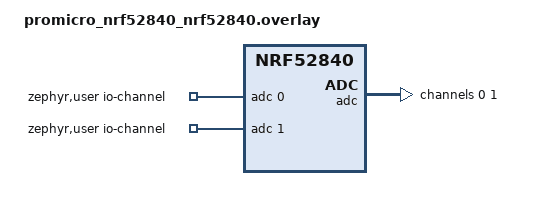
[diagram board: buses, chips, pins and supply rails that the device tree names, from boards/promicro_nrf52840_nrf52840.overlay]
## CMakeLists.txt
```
cmake_minimum_required(VERSION 3.20.0)
find_package(Zephyr REQUIRED HINTS $ENV{ZEPHYR_BASE})
project(duta_zephyr)

# The skrit contract + the shared portable core (header-only). src/ is on the
# path too so the portable common/duta_sniffer.h facade can include this
# platform's backend headers (duta_154_sniff.h / duta_ble_sniff.h).
target_include_directories(app PRIVATE
  ${CMAKE_CURRENT_SOURCE_DIR}/../../protocol
  ${CMAKE_CURRENT_SOURCE_DIR}/../common
  ${CMAKE_CURRENT_SOURCE_DIR}/src)
target_sources(app PRIVATE src/main.c)
target_sources_ifdef(CONFIG_DUTA_SNIFF app PRIVATE src/duta_ble_sniff.c)
target_sources_ifdef(CONFIG_DUTA_SNIFF_154 app PRIVATE src/duta_154_sniff.c)
# Unified build: both raw-radio backends + the runtime dispatch vtable.
target_sources_ifdef(CONFIG_DUTA_SNIFF_MULTI app PRIVATE
  src/duta_ble_sniff.c src/duta_154_sniff.c src/duta_sniffer_multi.c)
```

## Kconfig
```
# Duta zephyr app options.
config DUTA_SNIFF
	bool "Build the BLE advertising sniffer variant"
	depends on !BT && !DUTA_SNIFF_154 && !DUTA_SNIFF_MULTI
	help
	  Replace the UART DATA bridge with a raw-radio BLE advertising sniffer
	  (nRF only). The radio is driven directly — incompatible with the BLE
	  controller (BT) — to capture advertising PDUs on channels 37/38/39. DATA
	  becomes a stream of captured-packet records (kind = ble-sniff). Select via
	  `-DEXTRA_CONF_FILE=overlay-sniff.conf`.

config DUTA_SNIFF_154
	bool "Build the IEEE 802.15.4 (Zigbee/Thread) sniffer variant"
	depends on !BT && !DUTA_SNIFF_MULTI
	help
	  Replace the UART DATA bridge with a raw-radio IEEE 802.15.4 sniffer (nRF
	  only). The radio is driven directly in its 802.15.4 mode to capture frames
	  on channels 11-26 (Zigbee and Thread share this PHY/MAC). DATA becomes a
	  stream of captured-frame records (kind = ieee802154). One radio, so this is
	  mutually exclusive with the BLE sniffer. Select via
	  `-DEXTRA_CONF_FILE=overlay-sniff154.conf`.

config DUTA_SNIFF_MULTI
	bool "Build the unified runtime-switchable sniffer (BLE + 802.15.4)"
	depends on !BT
	help
	  Compile BOTH raw-radio sniffer backends into one image and switch the live
	  PHY at runtime via CFG_SET key 0x14 (DATA kind): 4 = BLE advertising
	  (channels 37/38/39), 7 = IEEE 802.15.4 (channels 11-26 — Zigbee, Thread,
	  and Matter-over-Thread, which share the PHY; the Wireshark dissector tells
	  them apart). DATA_DESC reflects the active link type so the extcap picks the
	  matching DLT. One nRF radio, so incompatible with the BLE controller (BT).
	  Boots in BLE mode. Select via `-DEXTRA_CONF_FILE=overlay-sniff-multi.conf`.

source "Kconfig.zephyr"
```

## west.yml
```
# Minimal west manifest so CI (and a fresh checkout) can resolve Zephyr.
# Inside an existing Zephyr workspace you don't need this — just `west build`.
manifest:
  remotes:
    - name: zephyrproject-rtos
      url-base: https://github.com/zephyrproject-rtos
  projects:
    - name: zephyr
      remote: zephyrproject-rtos
      revision: v4.2.0 # pinned so CI doesn't chase main; bump deliberately
      import:
        # Keep the CI clone lean — just what native_sim + nRF52840 need.
        name-allowlist:
          - cmsis
          - cmsis_6
          - hal_nordic
          - picolibc
  self:
    path: application
```

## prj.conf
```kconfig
# Common config — kept native_sim-safe (the CI build-check). USB/CDC and other
# board-specific bits live in boards/<board>.conf so they only apply on hardware.
CONFIG_PRINTK=y
CONFIG_GPIO=y
CONFIG_SERIAL=y
CONFIG_REBOOT=y
```

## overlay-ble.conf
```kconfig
# BLE transport overlay — carries the skrit-mux stream over a Nordic UART Service
# (NUS) GATT pipe instead of USB CDC. Build with:
#
#   west build -b nrf52840dk/nrf52840 platforms/zephyr -- -DEXTRA_CONF_FILE=overlay-ble.conf
#
# CONFIG_BT makes src/main.c select the BLE transport (see the #if CONFIG_BT block).
CONFIG_BT=y
CONFIG_BT_PERIPHERAL=y
CONFIG_BT_DEVICE_NAME="Duta nRF52840"
CONFIG_BT_DEVICE_APPEARANCE=0

# GATT server with our hand-rolled NUS service (BT_GATT_SERVICE_DEFINE).
CONFIG_BT_GATT_DYNAMIC_DB=y
CONFIG_BT_ATT_PREPARE_COUNT=2

# Larger ATT MTU so console bursts need fewer notifications.
CONFIG_BT_L2CAP_TX_MTU=247
CONFIG_BT_BUF_ACL_TX_SIZE=251
CONFIG_BT_BUF_ACL_RX_SIZE=251

# Security: LE Secure Connections pairing (ECDH P-256) so the air link is
# encrypted and NOT passively sniffable. A Duta has no display/keyboard, so the
# IO capability is NoInputNoOutput → "Just Works" pairing (encrypted, passively
# secure under LESC). The DATA/CMD characteristics require encryption, so a central
# must pair before it can write or subscribe.
CONFIG_BT_SMP=y
CONFIG_BT_BONDABLE=y

# Persist bonds across reboots: the settings subsystem over NVS on the flash map,
# so a paired host reconnects without re-pairing.
CONFIG_BT_SETTINGS=y
CONFIG_SETTINGS=y
CONFIG_FLASH=y
CONFIG_FLASH_MAP=y
CONFIG_NVS=y

# Per-device identity: set the advertised name to Duta-XXXX (from the BLE address)
# at runtime, so multiple Dutas are distinguishable in a scan.
CONFIG_BT_DEVICE_NAME_DYNAMIC=y
CONFIG_BT_DEVICE_NAME_MAX=24

# Keep the DATA-UART bridge + outputs + reboot from the base config.
CONFIG_SERIAL=y
CONFIG_GPIO=y
CONFIG_REBOOT=y
```

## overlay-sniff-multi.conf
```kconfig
# Unified runtime-switchable sniffer (BLE + IEEE 802.15.4), USB transport.
#   west build -b promicro_nrf52840/nrf52840 platforms/zephyr -- -DEXTRA_CONF_FILE=overlay-sniff-multi.conf
# Both raw-radio backends are compiled in and dispatched through a vtable; the
# host switches the live PHY at runtime with CFG_SET key 0x14 (DATA kind):
#   4 = BLE advertising · 7 = IEEE 802.15.4 (Zigbee / Thread / Matter-over-Thread)
# The radio is driven directly, so the BLE controller must stay off (BT=n, the
# default for the USB build). Boots in BLE mode.
CONFIG_DUTA_SNIFF_MULTI=y
# Carries the 802.15.4 backend (records up to ~137 B) — give the main stack the
# same headroom the single-154 build uses.
CONFIG_MAIN_STACK_SIZE=4096
```

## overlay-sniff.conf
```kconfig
# BLE advertising sniffer variant (USB transport).
#   west build -b promicro_nrf52840/nrf52840 platforms/zephyr -- -DEXTRA_CONF_FILE=overlay-sniff.conf
# The radio is driven directly, so the BLE controller must stay off (BT=n,
# the default for the USB build) and nothing else may claim the radio.
CONFIG_DUTA_SNIFF=y
```

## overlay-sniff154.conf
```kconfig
# IEEE 802.15.4 (Zigbee/Thread) sniffer variant (USB transport).
#   west build -b promicro_nrf52840/nrf52840 platforms/zephyr -- -DEXTRA_CONF_FILE=overlay-sniff154.conf
# The radio is driven directly in 802.15.4 mode, so the BLE controller must stay
# off (BT=n, the default for the USB build) and nothing else may claim the radio.
CONFIG_DUTA_SNIFF_154=y
# 802.15.4 records are large (up to ~137 B) and the enlarged send buffers push
# the main stack — give it headroom (the default is too tight for this path).
CONFIG_MAIN_STACK_SIZE=4096
```

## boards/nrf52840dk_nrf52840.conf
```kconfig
# nRF52840 DK — bring up the USB device stack + a CDC ACM port for the mux link,
# and the interrupt-driven UART API that cdc-acm needs.
CONFIG_USB_DEVICE_STACK=y
CONFIG_USB_DEVICE_PRODUCT="Duta nRF52840"
CONFIG_USB_DEVICE_VID=0x1209
CONFIG_USB_DEVICE_PID=0x5d10
CONFIG_USB_CDC_ACM=y
CONFIG_UART_INTERRUPT_DRIVEN=y
CONFIG_UART_LINE_CTRL=y
CONFIG_REBOOT=y
CONFIG_GPIO=y
```

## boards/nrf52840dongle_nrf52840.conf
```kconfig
# nRF52840 Dongle — same USB CDC ACM mux link as the DK. The dongle ships with a
# UF2/Open bootloader, so REBOOT(bootloader) drops straight back into DFU.
CONFIG_USB_DEVICE_STACK=y
CONFIG_USB_DEVICE_PRODUCT="Duta nRF52840 dongle"
CONFIG_USB_DEVICE_VID=0x1209
CONFIG_USB_DEVICE_PID=0x5d10
CONFIG_USB_CDC_ACM=y
CONFIG_UART_INTERRUPT_DRIVEN=y
CONFIG_UART_LINE_CTRL=y
CONFIG_REBOOT=y
CONFIG_GPIO=y
```

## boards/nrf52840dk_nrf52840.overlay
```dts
// nRF52840 DK — Duta transport map.
//   * CMD + DATA mux  -> a CDC ACM port on the USB device controller.
//   * DATA console     -> UART1 on header pins P1.01 (TX) / P1.02 (RX).
//   * Status LED       -> led0 (onboard) is the only default output; other
//                         fixtures are added at runtime via provisioning.
#include <zephyr/dt-bindings/pinctrl/nrf-pinctrl.h>

/ {
	aliases {
		duta-data = &uart1;
	};
};

&zephyr_udc0 {
	cdc_acm_uart0: cdc_acm_uart0 {
		compatible = "zephyr,cdc-acm-uart";
	};
};

&pinctrl {
	uart1_default: uart1_default {
		group1 {
			psels = <NRF_PSEL(UART_TX, 1, 1)>,
			        <NRF_PSEL(UART_RX, 1, 2)>;
		};
	};

	uart1_sleep: uart1_sleep {
		group1 {
			psels = <NRF_PSEL(UART_TX, 1, 1)>,
			        <NRF_PSEL(UART_RX, 1, 2)>;
			low-power-enable;
		};
	};
};

&uart1 {
	status = "okay";
	current-speed = <115200>;
	pinctrl-0 = <&uart1_default>;
	pinctrl-1 = <&uart1_sleep>;
	pinctrl-names = "default", "sleep";
};
```

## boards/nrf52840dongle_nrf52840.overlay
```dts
// nRF52840 Dongle — Duta transport map. The dongle has no debug UART, so DATA
// uses UART1 on two exposed castellated pads (P1.10 TX / P1.13 RX — adjust to
// your wiring). CMD + DATA still mux over a CDC ACM port. Outputs reuse the
// on-board LEDs (green led0 + two of the RGB channels).
#include <zephyr/dt-bindings/pinctrl/nrf-pinctrl.h>

/ {
	aliases {
		duta-data = &uart1;
	};
};

&zephyr_udc0 {
	cdc_acm_uart0: cdc_acm_uart0 {
		compatible = "zephyr,cdc-acm-uart";
	};
};

&pinctrl {
	uart1_default: uart1_default {
		group1 {
			psels = <NRF_PSEL(UART_TX, 1, 10)>,
			        <NRF_PSEL(UART_RX, 1, 13)>;
		};
	};

	uart1_sleep: uart1_sleep {
		group1 {
			psels = <NRF_PSEL(UART_TX, 1, 10)>,
			        <NRF_PSEL(UART_RX, 1, 13)>;
			low-power-enable;
		};
	};
};

&uart1 {
	status = "okay";
	current-speed = <115200>;
	pinctrl-0 = <&uart1_default>;
	pinctrl-1 = <&uart1_sleep>;
	pinctrl-names = "default", "sleep";
};
```

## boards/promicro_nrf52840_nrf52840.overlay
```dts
// Pro Micro nRF52840 — the "nice!nano v2 compatible" / SuperMini clone family.
// Board facts come from the upstream Zephyr board (boards/others/promicro_nrf52840):
//   * led0 = P0.15 (onboard blue LED), uart0 routed to the silkscreened TX/RX
//     pads (P0.09 TX / P0.10 RX; the NFC pins, freed as GPIO by the board UICR),
//     and a USB CDC ACM (cdc_acm_uart0) already in the board DTS.
// This overlay only adds OUR Duta wiring:
//   * CMD + DATA mux   -> the board's USB CDC ACM (BLE alt via overlay-ble.conf).
//   * DATA console      -> uart0, remapped to TX P0.06 / RX P0.08 (see &pinctrl).
//   * Status LED        -> led0 (the onboard blue LED) — the only default output.
//   External fixtures (relays, etc.) are NOT a compiled default: add them at
//   runtime via provisioning on the free broken-out pads.

#include <zephyr/dt-bindings/adc/adc.h>
#include <zephyr/dt-bindings/adc/nrf-saadc.h>
#include <zephyr/dt-bindings/pinctrl/nrf-pinctrl.h>

/ {
	aliases {
		duta-data = &uart0; // led0 (status LED) is already aliased by the board
	};

	// Two ADC inputs (skrit inputs 0 and 1), both internal — no broken-out pin:
	//   ch 0 = NRF_SAADC_VDD     → "Supply (mV)": the regulated rail (~3.0–3.3 V).
	//   ch 1 = NRF_SAADC_VDDHDIV5 → "Battery (mV)": VDDH/5; main.c ×5. On this
	//     nice!nano-clone family VDDH is fed from the LiPo (HV mode), so this reads
	//     the cell — but it tracks VDDH, so it reads HIGH on USB (~charge voltage),
	//     not the battery. The board's labelled P0.04 battery divider is mis-wired
	//     to P0.24 (no SAADC channel) upstream, so VDDHDIV5 is the usable path.
	// For an external analog pad instead, point a channel at <NRF_SAADC_AINx>
	// (AIN0 = P0.02, AIN2 = P0.04) and drop the ×5 in main.c for that index.
	zephyr,user {
		io-channels = <&adc 0>, <&adc 1>;
	};
};

&adc {
	status = "okay";
	#address-cells = <1>;
	#size-cells = <0>;

	channel@0 {
		reg = <0>;
		zephyr,gain = "ADC_GAIN_1_6";
		zephyr,reference = "ADC_REF_INTERNAL";
		zephyr,acquisition-time = <ADC_ACQ_TIME_DEFAULT>;
		zephyr,input-positive = <NRF_SAADC_VDD>;
		zephyr,resolution = <12>;
	};
	channel@1 {
		reg = <1>;
		zephyr,gain = "ADC_GAIN_1_6";
		zephyr,reference = "ADC_REF_INTERNAL";
		zephyr,acquisition-time = <ADC_ACQ_TIME_DEFAULT>;
		zephyr,input-positive = <NRF_SAADC_VDDHDIV5>; // battery via VDDH/5 (×5 in fw)
		zephyr,resolution = <12>;
	};
};

// Remap the DATA console (uart0) OFF the board-default silkscreen pads
// (P0.09 TX / P0.10 RX) to P0.06 TX / P0.08 RX. P0.10 is the nRF NFC1 pad — even
// with a pull-up it floats noisy as a UART RX and dumps garbage onto the Console
// (UART-bridge) source. P0.06/P0.08 are plain GPIO; bias RX high so an unwired
// bridge idles clean (a driven target overrides the weak pull). TX is an output
// and needs no bias. The sleep state is remapped to match.
&pinctrl {
	uart0_default {
		group1 {
			psels = <NRF_PSEL(UART_TX, 0, 6)>;
		};
		group2 {
			psels = <NRF_PSEL(UART_RX, 0, 8)>;
			bias-pull-up;
		};
	};
	uart0_sleep {
		group1 {
			psels = <NRF_PSEL(UART_TX, 0, 6)>,
				<NRF_PSEL(UART_RX, 0, 8)>;
			low-power-enable;
		};
	};
};
```

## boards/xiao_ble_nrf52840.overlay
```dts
// Seeed XIAO nRF52840 (Zephyr board xiao_ble). Board facts come from the upstream
// Zephyr board: uart0 is routed to the silkscreened TX/RX pads (D6 P1.11 / D7
// P1.12), there's a USB device controller (zephyr_udc0), and an onboard RGB user
// LED (led0 red P0.26, led1 green P0.30, led2 blue P0.06; active low), all of
// which the board already aliases. This overlay only adds OUR Duta wiring:
//   * CMD + DATA mux  -> a CDC ACM port on the USB device controller.
//   * DATA console     -> uart0 (the D6/D7 pads).
//   * Status LED       -> led0 (the RGB's red channel) — the only default output.
//     Relays / external fixtures are provisioned at runtime onto free pads via
//     Configure Device, not a fact about this board.

#include <zephyr/dt-bindings/adc/adc.h>
#include <zephyr/dt-bindings/adc/nrf-saadc.h>

/ {
	aliases {
		duta-data = &uart0; // led0/led1/led2 are already aliased by the board
	};

	// Two internal ADC inputs (skrit inputs 0/1): ch0 = VDD ("Supply (mV)", the
	// regulated rail); ch1 = VDDHDIV5 ("Battery (mV)", VDDH/5 ×5 in fw — the cell
	// on this nice!nano-class board, but reads high on USB). No pin needed.
	zephyr,user {
		io-channels = <&adc 0>, <&adc 1>;
	};
};

// The CDC ACM that carries the mux link (main.c looks for cdc_acm_uart0).
&zephyr_udc0 {
	cdc_acm_uart0: cdc_acm_uart0 {
		compatible = "zephyr,cdc-acm-uart";
	};
};

&uart0 {
	status = "okay";
	current-speed = <115200>;
};

&adc {
	status = "okay";
	#address-cells = <1>;
	#size-cells = <0>;

	channel@0 {
		reg = <0>;
		zephyr,gain = "ADC_GAIN_1_6";
		zephyr,reference = "ADC_REF_INTERNAL";
		zephyr,acquisition-time = <ADC_ACQ_TIME_DEFAULT>;
		zephyr,input-positive = <NRF_SAADC_VDD>;
		zephyr,resolution = <12>;
	};
	channel@1 {
		reg = <1>;
		zephyr,gain = "ADC_GAIN_1_6";
		zephyr,reference = "ADC_REF_INTERNAL";
		zephyr,acquisition-time = <ADC_ACQ_TIME_DEFAULT>;
		zephyr,input-positive = <NRF_SAADC_VDDHDIV5>; // battery via VDDH/5 (×5 in fw)
		zephyr,resolution = <12>;
	};
};
```

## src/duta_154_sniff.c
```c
// duta_154_sniff.c — raw-radio IEEE 802.15.4 sniffer (nRF52840).
// ============================================================================
// The ieee802154 DATA backend. With CONFIG_DUTA_SNIFF_154, the nRF radio is
// driven directly in its 802.15.4 mode (O-QPSK, 250 kbps) — the same silicon
// the BLE sniffer uses, different MODE. It listens promiscuously and captures
// MAC frames; each is emitted on the DATA channel as one record (PROTOCOL.md
// "IEEE 802.15.4 sniffer"):
//   ts_ms(4 LE) · channel(1, 11..26) · rssi(1, signed dBm) · lqi(1) ·
//     flags(1, bit0=FCS ok) · psdu_len(1) · psdu…
// The radio handles the O-QPSK PHY, the SFD, and the 16-bit FCS in hardware, so
// (unlike the BLE path) there's no software de-whitening; bad-FCS frames drop.
//
// Channel strategy: 802.15.4 networks live on ONE channel (not repeated across
// channels like BLE advertising), and we don't know which. So we dwell on a
// channel and hop to the next (11→26) only after it stays quiet for DWELL_MS,
// resetting the timer whenever a frame lands — i.e. we drift until we find the
// active channel, then stick there. (A fixed channel via CFG is a future knob.)
//
// NOTE: the radio register setup below follows the nRF52840 PS 802.15.4 mode;
// the values marked CONFIRM should be validated against live capture.
// ============================================================================
#include <nrfx.h> // MDK: NRF_RADIO + the RADIO_* register bitfields
#include <string.h>
#include <zephyr/kernel.h>

#include "duta_154_sniff.h"

// Implemented by the platform main: wakes the frame-consumer thread (event-driven
// instead of polling take()). Weak no-op default — matches the ESP backend's
// contract (duta_154_sniff_esp.c). This raw-register backend detects RX by polling
// EVENTS_END in take(), so it has no RX-complete callback to fire the hook from;
// it stays a default no-op here and the consumer thread's sem timeout drives the
// drain + channel hop. Wiring the RADIO END IRQ to call this is the future step
// (see NRF_ASYNC_REPORT.md) — left untouched because it can't be verified without
// hardware and a mis-armed radio IRQ would silently break capture.
__attribute__((weak)) void duta_sniffer_notify(void) {}

#define CH_MIN 11
#define CH_MAX 26
#define N_CHAN (CH_MAX - CH_MIN + 1)
#define DWELL_MS 400 // hop away from a quiet channel after this long

static uint8_t rx_buf[1 + 127 + 4]; // PHR(1) + max PSDU(127) + slack
static uint8_t tx_buf[1 + 127];     // PHR(1) + MAC frame (radio appends the FCS)
static uint8_t chan;                // current channel (11..26)
static uint8_t fixed_chan;          // 0 = auto-hop; 11..26 = pinned channel
static uint32_t last_hop_ms;
static bool sniff_active;

// 802.15.4 channel k (11..26) is 2405 + 5*(k-11) MHz; FREQUENCY = MHz - 2400.
static uint8_t chan_freq(uint8_t ch) { return (uint8_t)(5 * (ch - 10)); }

static void radio_arm(uint8_t ch) {
  NRF_RADIO->FREQUENCY = chan_freq(ch);
  NRF_RADIO->EVENTS_END = 0;
  NRF_RADIO->EVENTS_DISABLED = 0;
  NRF_RADIO->TASKS_RXEN = 1; // READY_START short kicks RX automatically
}

static void radio_rearm(uint8_t ch) {
  uint32_t guard = 100000;
  while (NRF_RADIO->STATE != RADIO_STATE_STATE_Disabled && guard--) { /* settle */ }
  radio_arm(ch);
}

void duta_154_sniff_init(void) {
  NRF_RADIO->POWER = 0;
  NRF_RADIO->POWER = 1;
  NRF_RADIO->MODE = (RADIO_MODE_MODE_Ieee802154_250Kbit << RADIO_MODE_MODE_Pos);
  // 802.15.4 on-air frame: PHR is one byte (7-bit length), no S0/S1. The length
  // field counts the PSDU *including* the 2-byte FCS (CRCINC = Include). The
  // radio frames on the SFD (0xA7) with a 32-bit zero preamble — no access addr.
  NRF_RADIO->PCNF0 = (8 << RADIO_PCNF0_LFLEN_Pos) |
                     (RADIO_PCNF0_PLEN_32bitZero << RADIO_PCNF0_PLEN_Pos) |
                     (RADIO_PCNF0_CRCINC_Include << RADIO_PCNF0_CRCINC_Pos);
  NRF_RADIO->PCNF1 = (127 << RADIO_PCNF1_MAXLEN_Pos); // no whitening, no base addr
  NRF_RADIO->SFD = 0xA7; // the 802.15.4 start-of-frame delimiter
  // 802.15.4 FCS: 16-bit, poly x^16+x^12+x^5+1 = 0x011021, init 0. SKIPADDR set
  // to the dedicated 802.15.4 value so the radio computes the FCS over the PSDU.
  NRF_RADIO->CRCCNF = (RADIO_CRCCNF_LEN_Two << RADIO_CRCCNF_LEN_Pos) |
                      (RADIO_CRCCNF_SKIPADDR_Ieee802154 << RADIO_CRCCNF_SKIPADDR_Pos);
  NRF_RADIO->CRCPOLY = 0x011021u;
  NRF_RADIO->CRCINIT = 0u;
  NRF_RADIO->PACKETPTR = (uint32_t)rx_buf;
  NRF_RADIO->SHORTS = RADIO_SHORTS_READY_START_Msk | RADIO_SHORTS_END_DISABLE_Msk |
                      RADIO_SHORTS_ADDRESS_RSSISTART_Msk;
}

void duta_154_sniff_start(void) {
  if (sniff_active) return;
  sniff_active = true;
  chan = fixed_chan ? fixed_chan : CH_MIN;
  last_hop_ms = k_uptime_get_32();
  radio_arm(chan);
}

void duta_154_sniff_set_channel(uint8_t ch) {
  fixed_chan = (ch >= CH_MIN && ch <= CH_MAX) ? ch : 0; // out of range => auto-hop
  chan = fixed_chan ? fixed_chan : CH_MIN;
  last_hop_ms = k_uptime_get_32();
  if (sniff_active) {
    NRF_RADIO->TASKS_DISABLE = 1;
    radio_rearm(chan); // retune now
  }
}

uint8_t duta_154_sniff_get_channel(void) { return chan; }

void duta_154_sniff_tx(const uint8_t *mac, uint16_t maclen) {
  if (maclen == 0 || maclen > 125) return; // +2 FCS must fit a 127-byte PSDU
  // Stop RX, transmit, then return to RX on the same channel. Single-threaded
  // with take(), so no concurrency with the receive path.
  NRF_RADIO->TASKS_DISABLE = 1;
  uint32_t guard = 100000;
  while (NRF_RADIO->STATE != RADIO_STATE_STATE_Disabled && guard--) { /* settle */ }

  tx_buf[0] = (uint8_t)(maclen + 2); // PHR length includes the 2-byte FCS (CRCINC)
  memcpy(tx_buf + 1, mac, maclen);   // the radio computes + appends the FCS
  NRF_RADIO->PACKETPTR = (uint32_t)tx_buf;
  NRF_RADIO->FREQUENCY = chan_freq(chan);
  NRF_RADIO->EVENTS_END = 0;
  NRF_RADIO->EVENTS_DISABLED = 0;
  NRF_RADIO->TASKS_TXEN = 1; // READY_START kicks TX; END_DISABLE disables after
  guard = 2000000;
  while (!NRF_RADIO->EVENTS_END && guard--) { /* wait for TX to finish */ }
  NRF_RADIO->EVENTS_END = 0;

  // Re-arm RX (restore the receive buffer first) if we're still sniffing.
  guard = 100000;
  while (NRF_RADIO->STATE != RADIO_STATE_STATE_Disabled && guard--) { /* settle */ }
  NRF_RADIO->PACKETPTR = (uint32_t)rx_buf;
  if (sniff_active) radio_arm(chan);
}

void duta_154_sniff_stop(void) {
  if (!sniff_active) return;
  sniff_active = false;
  NRF_RADIO->TASKS_DISABLE = 1;
  uint32_t guard = 100000;
  while (NRF_RADIO->STATE != RADIO_STATE_STATE_Disabled && guard--) { /* settle */ }
  NRF_RADIO->EVENTS_END = 0;
}

bool duta_154_sniff_is_on(void) { return sniff_active; }

uint16_t duta_154_sniff_take(uint8_t *out, uint16_t cap) {
  if (!sniff_active) return 0;

  if (!NRF_RADIO->EVENTS_END) {
    // No frame yet — hop away from a channel that has stayed quiet too long
    // (unless pinned to a fixed channel, in which case we just keep listening).
    if (!fixed_chan && (k_uptime_get_32() - last_hop_ms) >= DWELL_MS) {
      NRF_RADIO->TASKS_DISABLE = 1;
      chan = (uint8_t)(chan + 1);
      if (chan > CH_MAX) chan = CH_MIN;
      last_hop_ms = k_uptime_get_32();
      radio_rearm(chan);
    }
    return 0;
  }
  NRF_RADIO->EVENTS_END = 0;

  uint8_t crc_ok = (uint8_t)(NRF_RADIO->CRCSTATUS & 1u);
  int8_t rssi = (int8_t)(-(int32_t)(NRF_RADIO->RSSISAMPLE)); // magnitude -> signed dBm
  uint8_t cur = chan;
  uint8_t len = (uint8_t)(rx_buf[0] & 0x7Fu); // PHR length (PSDU incl. 2-byte FCS)

  // Traffic here — stay on this channel and re-arm. END_DISABLE already fired.
  last_hop_ms = k_uptime_get_32();
  radio_rearm(cur);

  if (!crc_ok || len < 2 || len > 127) return 0; // drop bad-FCS / impossible
  uint16_t need = 4 + 1 + 1 + 1 + 1 + 1 + len;
  if (need > cap) return 0;

  uint32_t ts = k_uptime_get_32();
  uint16_t n = 0;
  out[n++] = (uint8_t)ts;
  out[n++] = (uint8_t)(ts >> 8);
  out[n++] = (uint8_t)(ts >> 16);
  out[n++] = (uint8_t)(ts >> 24);
  out[n++] = cur;            // channel 11..26
  out[n++] = (uint8_t)rssi;  // signed dBm
  out[n++] = 0xFF;           // LQI not measured yet — placeholder (CONFIRM)
  out[n++] = 0x01;           // flags: bit0 = FCS ok (we dropped bad-FCS above)
  out[n++] = len;            // PSDU length (includes FCS)
  memcpy(out + n, rx_buf + 1, len);
  return (uint16_t)(n + len);
}
```

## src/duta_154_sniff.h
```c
// duta_154_sniff.h — raw-radio IEEE 802.15.4 sniffer (nRF; CONFIG_DUTA_SNIFF_154).
// Same shape as duta_ble_sniff.h, different radio mode — the nRF52840's radio
// also does 802.15.4 (the PHY/MAC under Zigbee AND Thread).
#ifndef DUTA_154_SNIFF_H
#define DUTA_154_SNIFF_H

#include <stdbool.h>
#include <stdint.h>

// Configure the radio for 802.15.4 sniffing (call once).
void duta_154_sniff_init(void);

// Start / stop capturing — backs the "Sniffing" virtual output. Idempotent.
void duta_154_sniff_start(void);
void duta_154_sniff_stop(void);
bool duta_154_sniff_is_on(void);

// If a frame was captured since the last call (and sniffing is on), write one
// DATA record into `out` (cap bytes) and return its length; else return 0. The
// sniffer dwells on a channel and hops (11..26) when it goes quiet, sticking
// wherever traffic appears. Record layout: see duta_154_sniff.c / PROTOCOL.md.
uint16_t duta_154_sniff_take(uint8_t *out, uint16_t cap);

// Pin the sniffer to one channel (11..26), or 0 to resume auto-hopping. Surfaced
// over SERIAL_SET (the baud field carries the channel). Takes effect immediately.
void duta_154_sniff_set_channel(uint8_t ch);
// The channel currently being listened on (the pinned one, or the live hop).
uint8_t duta_154_sniff_get_channel(void);

// Transmit one 802.15.4 MAC frame (WITHOUT FCS — the radio appends it) on the
// current channel, then return to RX. `mac`/`maclen` is the on-air MAC frame the
// host built. Backs DATA-channel writes: the host injects by writing a frame.
void duta_154_sniff_tx(const uint8_t *mac, uint16_t maclen);

#endif // DUTA_154_SNIFF_H
```

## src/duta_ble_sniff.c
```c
// duta_ble_sniff.c — raw-radio BLE advertising sniffer (nRF52840).
// ============================================================================
// The ble-sniff DATA backend. With CONFIG_DUTA_SNIFF, the nRF radio is driven
// directly (NOT the BLE controller — CONFIG_BT must be off) to listen
// promiscuously on the three BLE advertising channels and capture PDUs. Each
// captured packet is emitted on the DATA channel as one record (PROTOCOL.md
// "BLE sniffer"):
//   ts_ms(4 LE) · channel(1) · rssi(1, -dBm) · access-address(4 LE) · pdu_len(1) · pdu…
// The pdu is the on-air advertising PDU (2-byte header + payload), de-whitened
// and CRC-checked by the radio. Connection-following / data channels are out of
// scope for this MVP (advertising only).
// ============================================================================
#include <nrfx.h> // brings in the MDK: NRF_RADIO + the RADIO_* register bitfields
#include <string.h>
#include <zephyr/kernel.h>

#include "duta_ble_sniff.h"

#define ADV_ACCESS_ADDR 0x8E89BED6u // the fixed BLE advertising access address

static uint8_t rx_buf[2 + 257];                  // header(2) + max payload
static const uint8_t adv_chan[3] = {37, 38, 39}; // BLE advertising channel indices
static const uint8_t adv_freq[3] = {2, 26, 80};  // 2402 / 2426 / 2480 MHz (FREQUENCY reg)
static uint8_t chan_i;
static bool sniff_active; // start/stop gate (the "Sniffing" virtual output)

static void radio_arm(uint8_t i) {
  NRF_RADIO->FREQUENCY = adv_freq[i];
  NRF_RADIO->DATAWHITEIV = adv_chan[i]; // whitening IV = channel index (bit6 forced by HW)
  NRF_RADIO->EVENTS_END = 0;
  NRF_RADIO->EVENTS_DISABLED = 0;
  NRF_RADIO->TASKS_RXEN = 1; // READY_START short kicks RX automatically
}

void duta_sniff_init(void) {
  NRF_RADIO->POWER = 0;
  NRF_RADIO->POWER = 1;
  NRF_RADIO->MODE = (RADIO_MODE_MODE_Ble_1Mbit << RADIO_MODE_MODE_Pos);
  // BLE adv on-air packet: 1-byte S0 (PDU header byte 0), 8-bit LENGTH, no S1.
  NRF_RADIO->PCNF0 = (1 << RADIO_PCNF0_S0LEN_Pos) | (8 << RADIO_PCNF0_LFLEN_Pos);
  NRF_RADIO->PCNF1 = (RADIO_PCNF1_WHITEEN_Enabled << RADIO_PCNF1_WHITEEN_Pos) |
                     (RADIO_PCNF1_ENDIAN_Little << RADIO_PCNF1_ENDIAN_Pos) |
                     (3 << RADIO_PCNF1_BALEN_Pos) | // 3 base bytes + 1 prefix = 4-byte AA
                     (255 << RADIO_PCNF1_MAXLEN_Pos);
  NRF_RADIO->BASE0 = (ADV_ACCESS_ADDR << 8);        // 0x89BED600
  NRF_RADIO->PREFIX0 = (ADV_ACCESS_ADDR >> 24) & 0xFF; // 0x8E
  NRF_RADIO->RXADDRESSES = 1;                       // listen on logical address 0
  // BLE CRC: 24-bit, computed over the PDU (skip the access address), init 0x555555.
  NRF_RADIO->CRCCNF = (RADIO_CRCCNF_LEN_Three << RADIO_CRCCNF_LEN_Pos) |
                      (RADIO_CRCCNF_SKIPADDR_Skip << RADIO_CRCCNF_SKIPADDR_Pos);
  NRF_RADIO->CRCPOLY = 0x100065Bu;
  NRF_RADIO->CRCINIT = 0x555555u;
  NRF_RADIO->PACKETPTR = (uint32_t)rx_buf;
  NRF_RADIO->SHORTS = RADIO_SHORTS_READY_START_Msk | RADIO_SHORTS_END_DISABLE_Msk |
                      RADIO_SHORTS_ADDRESS_RSSISTART_Msk;
}

void duta_sniff_start(void) {
  if (sniff_active) return;
  sniff_active = true;
  chan_i = 0;
  radio_arm(chan_i);
}

void duta_sniff_stop(void) {
  if (!sniff_active) return;
  sniff_active = false;
  NRF_RADIO->TASKS_DISABLE = 1;
  uint32_t guard = 100000;
  while (NRF_RADIO->STATE != RADIO_STATE_STATE_Disabled && guard--) { /* settle */ }
  NRF_RADIO->EVENTS_END = 0;
}

bool duta_sniff_is_on(void) { return sniff_active; }

uint16_t duta_sniff_take(uint8_t *out, uint16_t cap) {
  if (!sniff_active || !NRF_RADIO->EVENTS_END) return 0; // stopped, or nothing captured
  NRF_RADIO->EVENTS_END = 0;

  uint8_t crc_ok = (uint8_t)(NRF_RADIO->CRCSTATUS & 1u);
  uint8_t rssi = (uint8_t)NRF_RADIO->RSSISAMPLE; // magnitude in -dBm
  uint8_t ch = adv_chan[chan_i];
  uint8_t pdu_len = (uint8_t)(2 + rx_buf[1]); // header(2) + payload length field

  // hop to the next advertising channel and re-arm (END_DISABLE already fired)
  chan_i = (uint8_t)((chan_i + 1) % 3);
  uint32_t guard = 100000;
  while (NRF_RADIO->STATE != RADIO_STATE_STATE_Disabled && guard--) { /* spin briefly */ }
  radio_arm(chan_i);

  if (!crc_ok || pdu_len > 39) return 0; // drop corrupt / over-long captures
  uint16_t need = 4 + 1 + 1 + 4 + 1 + pdu_len;
  if (need > cap) return 0;

  uint32_t ts = k_uptime_get_32();
  uint32_t aa = ADV_ACCESS_ADDR;
  uint16_t n = 0;
  out[n++] = (uint8_t)ts;
  out[n++] = (uint8_t)(ts >> 8);
  out[n++] = (uint8_t)(ts >> 16);
  out[n++] = (uint8_t)(ts >> 24);
  out[n++] = ch;
  out[n++] = rssi;
  out[n++] = (uint8_t)aa;
  out[n++] = (uint8_t)(aa >> 8);
  out[n++] = (uint8_t)(aa >> 16);
  out[n++] = (uint8_t)(aa >> 24);
  out[n++] = pdu_len;
  memcpy(out + n, rx_buf, pdu_len);
  return (uint16_t)(n + pdu_len);
}
```

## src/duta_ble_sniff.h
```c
// duta_ble_sniff.h — raw-radio BLE advertising sniffer (nRF; CONFIG_DUTA_SNIFF).
#ifndef DUTA_BLE_SNIFF_H
#define DUTA_BLE_SNIFF_H

#include <stdbool.h>
#include <stdint.h>

// Configure the radio for BLE advertising sniffing (call once).
void duta_sniff_init(void);

// Start / stop capturing — backs the "Sniffing" virtual output. Idempotent.
void duta_sniff_start(void);
void duta_sniff_stop(void);
bool duta_sniff_is_on(void);

// If a packet was captured since the last call (and sniffing is on), write one
// DATA record into `out` (cap bytes) and return its length; else return 0.
// Re-arms RX (hopping 37→38→39). Record layout: see duta_ble_sniff.c / PROTOCOL.md.
uint16_t duta_sniff_take(uint8_t *out, uint16_t cap);

#endif // DUTA_BLE_SNIFF_H
```

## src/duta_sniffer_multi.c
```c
// duta_sniffer_multi.c — unified runtime-switchable radio sniffer (nRF52840).
// ============================================================================
// Compiles BOTH raw-radio backends (BLE advertising + IEEE 802.15.4) into one
// image and dispatches the portable duta_sniffer_* contract through a vtable to
// whichever is active. One radio, so exactly one PHY is configured at a time;
// switching fully re-inits the radio for the target backend (each *_init writes
// all the MODE/PCNF/CRC/SHORTS registers, so no residue carries over).
//
// The host switches at runtime with CFG_SET key 0x14 (SKRIT_CFG_DATA_KIND):
//   kind 4 = ble-sniff   → BLE advertising (channels 37/38/39, RX only for now)
//   kind 7 = ieee802154  → Zigbee / Thread / Matter-over-Thread (channels 11-26,
//                          TX + channel select). The three share the 802.15.4
//                          PHY — only the Wireshark dissector differs.
// main.c's cfg_set calls duta_sniffer_select() and updates the HAL data_kind so
// DATA_DESC reports the active link type (the extcap probes it to pick the DLT).
// ============================================================================
#include "duta_sniffer.h"

#include "duta_154_sniff.h"
#include "duta_ble_sniff.h"
#include "protocol.h" // SKRIT_DATA_*

typedef struct {
  uint8_t kind;
  bool has_tx;
  void (*init)(void);
  void (*start)(void);
  void (*stop)(void);
  bool (*is_on)(void);
  uint16_t (*take)(uint8_t *, uint16_t);
  void (*set_channel)(uint8_t);
  uint8_t (*get_channel)(void);
  void (*tx)(const uint8_t *, uint16_t);
} sniff_vt;

// The BLE backend is RX-only and hops adv channels internally — no channel/TX.
static void ble_set_channel(uint8_t ch) { (void)ch; }
static uint8_t ble_get_channel(void) { return 0; } // 0 = auto/hop
static void ble_no_tx(const uint8_t *p, uint16_t n) {
  (void)p;
  (void)n;
}

static const sniff_vt VT_BLE = {
    .kind = SKRIT_DATA_BLE_SNIFF,
    .has_tx = false,
    .init = duta_sniff_init,
    .start = duta_sniff_start,
    .stop = duta_sniff_stop,
    .is_on = duta_sniff_is_on,
    .take = duta_sniff_take,
    .set_channel = ble_set_channel,
    .get_channel = ble_get_channel,
    .tx = ble_no_tx,
};
static const sniff_vt VT_154 = {
    .kind = SKRIT_DATA_IEEE802154,
    .has_tx = true,
    .init = duta_154_sniff_init,
    .start = duta_154_sniff_start,
    .stop = duta_154_sniff_stop,
    .is_on = duta_154_sniff_is_on,
    .take = duta_154_sniff_take,
    .set_channel = duta_154_sniff_set_channel,
    .get_channel = duta_154_sniff_get_channel,
    .tx = duta_154_sniff_tx,
};

// Boots in BLE-sniff mode (matches DUTA_SNIFF_KIND in duta_sniffer.h).
static const sniff_vt *active = &VT_BLE;

void duta_sniffer_init(void) { active->init(); }
void duta_sniffer_start(void) { active->start(); }
void duta_sniffer_stop(void) { active->stop(); }
bool duta_sniffer_is_on(void) { return active->is_on(); }
uint16_t duta_sniffer_take(uint8_t *out, uint16_t cap) { return active->take(out, cap); }
void duta_sniffer_set_channel(uint8_t ch) { active->set_channel(ch); }
uint8_t duta_sniffer_get_channel(void) { return active->get_channel(); }
void duta_sniffer_tx(const uint8_t *frame, uint16_t len) {
  if (active->has_tx) active->tx(frame, len);
}
uint8_t duta_sniffer_kind(void) { return active->kind; }

bool duta_sniffer_select(uint8_t kind) {
  const sniff_vt *target = (kind == SKRIT_DATA_BLE_SNIFF)    ? &VT_BLE
                           : (kind == SKRIT_DATA_IEEE802154) ? &VT_154
                                                             : NULL;
  if (target == NULL || target == active) return false;
  bool was_on = active->is_on();
  active->stop();      // disable the radio in the old PHY
  active = target;
  active->init();      // reconfigure all RADIO registers for the new PHY
  if (was_on) active->start();
  return true;
}
```
